# DA14586 register map
Vendor: Dialog; Series: DA1458x; File version: 1.2
CPU: CM0 r1p0, little endian, MPU, FPU, 3 interrupt priority bits
Registers are 16-bit, read-write, reset 0x0 unless marked. A register's access mark holds for its fields unless they carry their own. Offsets are from the block's base; [hi:lo] are bit positions; {n}, {i} and the like mark numbered series.

## ble580_gr01 — ble580_gr01 registers
Base 0x40000000
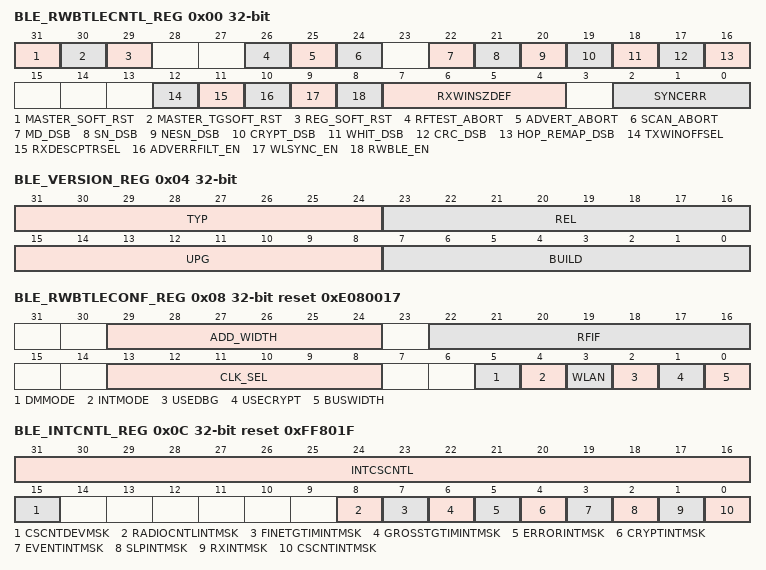
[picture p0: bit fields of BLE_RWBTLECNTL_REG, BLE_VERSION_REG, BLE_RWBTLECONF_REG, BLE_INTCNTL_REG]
0x00 BLE_RWBTLECNTL_REG 32-bit (reset mask 0x7FFFFFFF) — BLE Control register
  [31] MASTER_SOFT_RST — Reset the complete system except registers and timing generator, when written with a 1. Resets at 0 when action is performed. No action happens if it is written with 0.
  [30] MASTER_TGSOFT_RST — Reset the timing generator, when written with a 1. Resets at 0 when action is performed. No action happens if it is written with 0.
  [29] REG_SOFT_RST — Reset the complete register block, when written with a 1. Resets at 0 when action is performed. No action happens if it is written with 0.
  [26] RFTEST_ABORT — Abort the current RF Testing defined as per CS-FORMAT when written with a 1. Resets at 0 when action is performed. No action happens if it is written with 0. Note that when RFTEST_ABORT is requested. 1) In case of infinite Tx, the Packet Controller FSM stops at the end of the current byte in process, and processes accordingly the packet CRC. 2) In case of Infinite Rx, the Packet Controller FSM either stops as the end of the current Packet reception (if Access address has been detected), or simply stop the processing switching off the RF.
  [25] ADVERT_ABORT — Abort the current Advertising event when written with a 1. Resets at 0 when action is performed. No action happens if it is written with 0.
  [24] SCAN_ABORT — Abort the current scan window when written with a 1. Resets at 0 when action is performed. No action happens if it is written with 0.
  [22] MD_DSB — 0: Normal operation of MD bits management 1: Allow a single Tx/Rx exchange whatever the MD bits are
  [21] SN_DSB — 0: Normal operation of Sequence number 1: Sequence Number Management disabled: value forced by SW from Tx Descriptor value ignored in Rx, meaning that no SN error reported.
  [20] NESN_DSB — 0: Normal operation of Sequence number 1: Sequence Number Management disabled: value forced by SW from Tx Descriptor value ignored in Rx, meaning that no SN error reported.
  [19] CRYPT_DSB — 0: Normal operation. Encryption / Decryption enabled. 1: Encryption / Decryption disabled. Note that if CS-CRYPT_EN is set, then MIC is generated, and only data encryption is disabled, meaning data sent are plain data.
  [18] WHIT_DSB — 0: Normal operation. Whitening enabled. 1: Whitening disabled.
  [17] CRC_DSB — 0: Normal operation. CRC removed from data stream. 1: CRC stripping disabled on Rx packets, CRC replaced by 0x000 in Tx
  [16] HOP_REMAP_DSB — 0: Normal operation. Frequency Hopping Remapping algorithm enabled. 1: Frequency Hopping Remapping algorithm disabled
  [12] TXWINOFFSEL — Applicable only if device is in Initiator mode 0: Window Offset field in CONNECT_REQ comes from Tx Data Buffer 1: Window Offset field in CONNECT_REQ comes from Event Controller processing and is replaced in real time by Packet Controller
  [11] RXDESCPTRSEL — 0: Selects Rx Descriptor Pointer value from Control Structure 1: Selects Rx Descriptor Pointer value from CURRENTRXDESCPTR register
  [10] ADVERRFILT_EN — Advertising Channels Error Filtering Enable control 0: BLE Core reports all errors to BLE Software 1: BLE Core reports only correctly received packet, without error to BLE Software
  [9] WLSYNC_EN — 0: WLAN synchronization pulse generation disabled 1: WLAN synchronization pulse generation enabled
  [8] RWBLE_EN — 0: Disable BLE Core Exchange Table pre-fetch mechanism. 1: Enable BLE Core Exchange table pre-fetch mechanism.
  [7:4] RXWINSZDEF — Default Rx Window size in us. Used when device a) is master connected b) performs its second receipt. 0 is not a valid value. Recommended value is 10.
  [2:0] SYNCERR — Indicates the maximum number of errors allowed to recognize the synchronization word.
0x04 BLE_VERSION_REG 32-bit (reset mask 0x7FFFFFFF) — Version register
  [31:24] TYP ro — BLE Core Type - 0x6 means BT4.0 (i.e correspond LL version assigned number)
  [23:16] REL ro — BLE Core version - Major release number.(Correspond to FS v1.11)
  [15:8] UPG ro — BLE Core upgrade - Upgrade number. (Correspond to FS v1.11)
  [7:0] BUILD ro — BLE Core Build - Build number
0x08 BLE_RWBTLECONF_REG 32-bit reset 0xE080017 — Configuration register
  [29:24] ADD_WIDTH ro — Value of the BLE_ADDRESS_WIDTH parameter converted into binary.
  [22:16] RFIF ro — Supported radio interfaces. 0001000: on-chip radio others: reserved
  [13:8] CLK_SEL ro — Operating Frequency (in MHz). This field is a copy of the BLE_CNTL2_REG[BLE_CLK_SEL] value.
  [5] DMMODE ro — 0: BLE Core is used as a standalone BLE device 1: BLE Core is used in a Dual Mode device
  [4] INTMODE ro — 0: Interrupts are edge level generated, i.e pulse. 1: Interrupts are trigger level generated, i.e stays active at 1 till acknowledgement
  [3] WLAN ro — 0: WLAN Coexistence mechanism not present 1: WLAN Coexistence mechanism present
  [2] USEDBG ro — 0: Diagnostic port not instantiated 1: Diagnostic port instantiated
  [1] USECRYPT ro — 0: Encryption block not present 1: Encryption block present
  [0] BUSWIDTH ro — Processor bus width: 0: 16 bits 1: 32 bits
0x0C BLE_INTCNTL_REG 32-bit reset 0xFF801F (reset mask 0x7FFFFFFF) — Interrupt controller register
  [31:16] INTCSCNTL — Selection of the CS counter that generates an interrupt. For example, if INTCNTL[3] is set, an interrupt is sent each time CS counter equals 3.
  [15] CSCNTDEVMSK — CSCNT interrupt mask during event. This bit allows to enable CSCNT interrupt generation during events (i.e advertising, scanning, initiating, and connection) 0: CSCNT Interrupt not generated during events. 1: CSCNT Interrupt generated during events.
  [8] RADIOCNTLINTMSK — Radio Controller interrupt mask 0: Interrupt not generated 1: Interrupt generated
  [7] FINETGTIMINTMSK — Fine Target Timer Mask 0: Interrupt not generated 1: Interrupt generated
  [6] GROSSTGTIMINTMSK — Gross Target Timer Mask 0: Interrupt not generated 1: Interrupt generated
  [5] ERRORINTMSK — Error Interrupt Mask 0: Interrupt not generated 1: Interrupt generated
  [4] CRYPTINTMSK — Encryption / Decryption Interrupt Mask 0: Interrupt not generated 1: Interrupt generated
  [3] EVENTINTMSK — End of event Interrupt Mask 0: Interrupt not generated 1: Interrupt generated
  [2] SLPINTMSK — Sleep Mode Interrupt Mask 0: Interrupt not generated 1: Interrupt generated
  [1] RXINTMSK — Rx Interrupt Mask 0: Interrupt not generated 1: Interrupt generated
  [0] CSCNTINTMSK — 625usec Base Time Interrupt Mask. 0: Interrupt not generated. 1: Interrupt generated
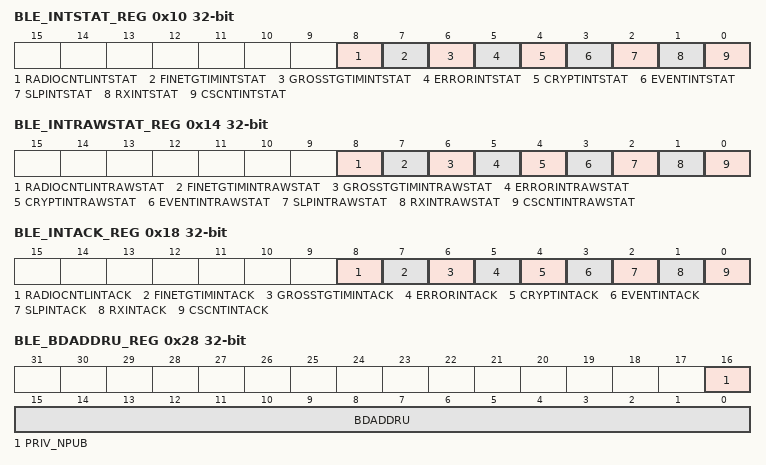
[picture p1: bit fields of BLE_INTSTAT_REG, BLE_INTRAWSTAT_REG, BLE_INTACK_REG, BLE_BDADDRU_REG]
0x10 BLE_INTSTAT_REG 32-bit — Interrupt status register
  [8] RADIOCNTLINTSTAT ro — Radio Controller interrupt status 0: No Gross Target Timer interrupt. 1: A Gross Target Timer interrupt is pending.
  [7] FINETGTIMINTSTAT ro — Masked Fine Target Timer Error interrupt status 0: No Fine Target Timer interrupt. 1: A Fine Target Timer interrupt is pending.
  [6] GROSSTGTIMINTSTAT ro — Masked Gross Target Timer interrupt status 0: No Gross Target Timer interrupt. 1: A Gross Target Timer interrupt is pending.
  [5] ERRORINTSTAT ro — Masked Error interrupt status 0: No Error interrupt. 1: An Error interrupt is pending.
  [4] CRYPTINTSTAT ro — Masked Encryption/Decryption interrupt status 0: No Encryption / Decryption interrupt. 1: An Encryption / Decryption interrupt is pending.
  [3] EVENTINTSTAT ro — Masked End of Event interrupt status 0: No End of Advertising / Scanning / Connection interrupt. 1: An End of Advertising / Scanning / Connection interrupt is pending.
  [2] SLPINTSTAT ro — Masked Sleep interrupt status 0: No End of Sleep Mode interrupt. 1: An End of Sleep Mode interrupt is pending.
  [1] RXINTSTAT ro — Masked Packet Reception interrupt status 0: No Rx interrupt. 1: An Rx interrupt is pending.
  [0] CSCNTINTSTAT ro — Masked 625us base time reference interrupt status 0: No 625us Base Time interrupt. 1: A 625us Base Time interrupt is pending.
0x14 BLE_INTRAWSTAT_REG 32-bit — Interrupt raw status register
  [8] RADIOCNTLINTRAWSTAT ro — Radio Controller interrupt raw status 0: No Gross Target Timer interrupt. 1: A Gross Target Timer interrupt is pending.
  [7] FINETGTIMINTRAWSTAT ro — Fine Target Timer Error interrupt raw status 0: No Fine Target Timer interrupt. 1: A Fine Target Timer interrupt is pending.
  [6] GROSSTGTIMINTRAWSTAT ro — Gross Target Timer interrupt raw status 0: No Gross Target Timer interrupt. 1: A Gross Target Timer interrupt is pending.
  [5] ERRORINTRAWSTAT ro — Error interrupt raw status 0: No Error interrupt. 1: An Error interrupt is pending.
  [4] CRYPTINTRAWSTAT ro — Encryption/Decryption interrupt raw status 0: No Encryption / Decryption interrupt. 1: An Encryption / Decryption interrupt is pending.
  [3] EVENTINTRAWSTAT ro — End of Event interrupt raw status 0: No End of Advertising / Scanning / Connection interrupt. 1: An End of Advertising / Scanning / Connection interrupt is pending.
  [2] SLPINTRAWSTAT ro — Sleep interrupt raw status 0: No End of Sleep Mode interrupt. 1: An End of Sleep Mode interrupt is pending.
  [1] RXINTRAWSTAT ro — Packet Reception interrupt raw status 0: No Rx interrupt. 1: An Rx interrupt is pending.
  [0] CSCNTINTRAWSTAT ro — 625us base time reference interrupt raw status 0: No 625us Base Time interrupt. 1: A 625us Base Time interrupt is pending.
0x18 BLE_INTACK_REG 32-bit — Interrupt acknowledge register
  [8] RADIOCNTLINTACK wo — Radio Controller interrupt acknowledgement bit Software writing 1 acknowledges the Error interrupt. This bit resets RADIOCNTLINTSTAT and RADIOCNTLINTRAWSTAT flags.
  [7] FINETGTIMINTACK wo — Fine Target Timer interrupt acknowledgement bit Software writing 1 acknowledges the Error interrupt. This bit resets FINETGTIMINTSTAT and FINETGTIMINTRAWSTAT flags.
  [6] GROSSTGTIMINTACK wo — Gross Target Timer interrupt acknowledgement bit Software writing 1 acknowledges the Error interrupt. This bit resets GROSSTGTIMINTSTAT and GROSSTGTIMINTRAWSTAT flags.
  [5] ERRORINTACK wo — Error interrupt acknowledgement bit Software writing 1 acknowledges the Error interrupt. This bit resets ERRORINTSTAT and ERRORINTRAWSTAT flags.
  [4] CRYPTINTACK wo — Encryption/Decryption interrupt acknowledgement bit Software writing 1 acknowledges the Encryption / Decryption interrupt. This bit resets CRYPTINTSTAT and CRYPTINTRAWSTAT flags.
  [3] EVENTINTACK wo — End of Event interrupt acknowledgment bit Software writing 1 acknowledges the End of Advertising / Scanning / Connection interrupt. This bit resets SLPINTSTAT and SLPINTRAWSTAT flags.
  [2] SLPINTACK wo — End of Deep Sleep interrupt acknowledgment bit Software writing 1 acknowledges the End of Sleep Mode interrupt. This bit resets SLPINTSTAT and SLPINTRAWSTAT flags.
  [1] RXINTACK wo — Packet Reception interrupt acknowledgment bit Software writing 1 acknowledges the Rx interrupt. This bit resets RXINTSTAT and RXINTRAWSTAT flags.
  [0] CSCNTINTACK wo — 625us base time reference interrupt acknowledgment bit Software writing 1 acknowledges the CLKN interrupt. This bit resets CLKINTSTAT and CLKINTRAWSTAT flags.
0x1C BLE_BASETIMECNT_REG 32-bit — Base time reference counter
  [26:0] BASETIMECNT ro — Value of the 625us base time reference counter. Updated each time BLE_SAMPLECLK_REG[SAMP] is written. Used by the SW in order to synchronize with the HW.
0x20 BLE_FINETIMECNT_REG 32-bit — Fine time reference counter
  [9:0] FINECNT ro — Value of the current usec fine time reference counter. Updated each usec. Used by the SW in order to synchronize with the HW, and obtain a more precise sleep duration
0x24 BLE_BDADDRL_REG 32-bit (reset mask 0x7FFFFFFF) — BLE device address LSB register
  [31:0] BDADDRL — Bluetooth Low Energy Device Address. LSB part.
0x28 BLE_BDADDRU_REG 32-bit — BLE device address MSB register
  [16] PRIV_NPUB — Bluetooth Low Energy Device Address privacy indicator 0: Public Bluetooth Device Address 1: Private Bluetooth Device Address
  [15:0] BDADDRU — Bluetooth Low Energy Device Address. MSB part.
0x2C BLE_CURRENTRXDESCPTR_REG 32-bit — Rx Descriptor Pointer for the Receive Buffer Chained List
  [13:0] CURRENTRXDESCPTR — Rx Descriptor Pointer that determines the starting point of the Receive Buffer Chained List.
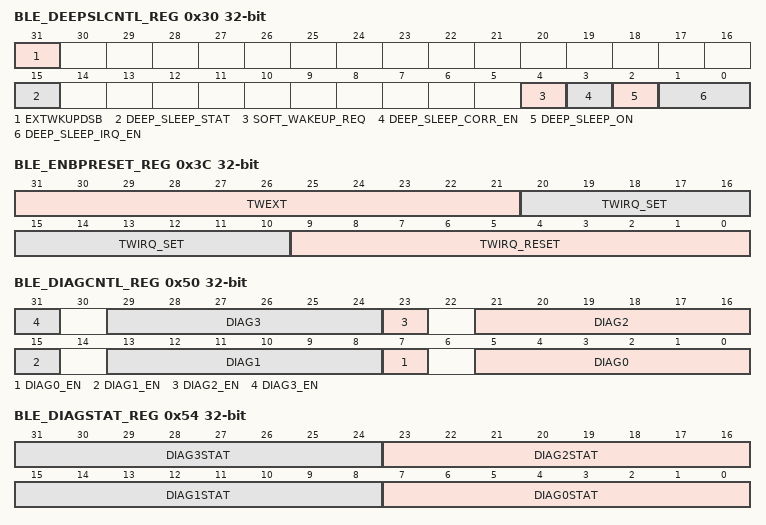
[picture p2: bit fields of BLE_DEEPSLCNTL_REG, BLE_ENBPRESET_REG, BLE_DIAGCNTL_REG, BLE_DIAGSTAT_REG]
0x30 BLE_DEEPSLCNTL_REG 32-bit (reset mask 0x7FFFFFFF) — Deep-Sleep control register
  [31] EXTWKUPDSB — External Wake-Up disable 0: BLE Core can be woken by external wake-up 1: BLE Core cannot be woken up by external wake-up
  [15] DEEP_SLEEP_STAT ro — Indicator of current Deep Sleep clock mux status: 0: BLE Core is not yet in Deep Sleep Mode 1: BLE Core is in Deep Sleep Mode (only Low Power Clock is running)
  [4] SOFT_WAKEUP_REQ — Wake Up Request from BLE Software. Applies when system is in Deep Sleep Mode. It wakes up the BLE Core when written with a 1. Always read as 0. No action happens if it is written with 0.
  [3] DEEP_SLEEP_CORR_EN — 625us base time reference integer and fractional part correction. Applies when system has been woken-up from Deep Sleep Mode. It enables Fine Counter and Base Time counter when written with a 1. Always read as 0. No action happens if it is written with 0.
  [2] DEEP_SLEEP_ON — 0: BLE Core in normal active mode 1: Request BLE Core to switch in deep sleep mode. This bit is reset on DEEP_SLEEP_STAT falling edge.
  [1:0] DEEP_SLEEP_IRQ_EN — Always set to '3' when DEEP_SLEEP_ON is set to '1'. It controls the generation of BLE_WAKEUP_LP_IRQ.
0x34 BLE_DEEPSLWKUP_REG 32-bit (reset mask 0x7FFFFFFF) — Time (measured in Low Power clock cycles) in Deep Sleep Mode before waking-up the device
  [31:0] DEEPSLTIME — Determines the time in Low Power Clock cycles to spend in Deep Sleep Mode before waking-up the device. This ensures a maximum of 37 hours and 16mn sleep mode capabilities at 32kHz. This ensures a maximum of 36 hours and 16mn sleep mode capabilities at 32.768kHz. If DEEPSLTIME is set to zero, the Deep Sleep Time duration is considered as infinite, and only wake up requests can restore active behaviour BLE Software must ensure DEEPSLTIME value to be greater than 2 in order to cope with control resynchronization requirements
0x38 BLE_DEEPSLSTAT_REG 32-bit (reset mask 0x7FFFFFFF) — Duration of the last deep sleep phase register
  [31:0] DEEPSLDUR ro — Actual duration of the last deep sleep phase measured in Low Power Clock cycles. DEEPSLDUR is set to zero at the beginning of the deep sleep phase, and is incremented at each Low Power Clock cycle until the end of the deep sleep phase.
0x3C BLE_ENBPRESET_REG 32-bit (reset mask 0x7FFFFFFF) — Time in low power oscillator cycles register
  [31:21] TWEXT — Minimum and recommended value is 'TWIRQ_RESET + 1'. In the case of wake-up due to an external wake-up request, TWEXT specifies the time delay in low power oscillator cycles to deassert BLE_WAKEUP_LP_IRQ. Refer also to GP_CONTROL_REG[BLE_WAKEUP_REQ]. Range is [0...64 ms] for 32kHz; [0...62.5 ms] for 32.768kHz
  [20:10] TWIRQ_SET — Minimum value is 'TWIRQ_RESET + 1'. Time in low power oscillator cycles to set BLE_WAKEUP_LP_IRQ before the BLE sleep timer expiration. Refer also to BLE_DEEPSLWKUP_REG[DEEPSLTIME]. Range is [0...64 ms] for 32kHz; [0...62.5 ms] for 32.768kHz
  [9:0] TWIRQ_RESET — Recommended value is 1. Time in low power oscillator cycles to reset BLE_WAKEUP_LP_IRQ before the BLE sleep timer expiration. Refer also to BLE_DEEPSLWKUP_REG[DEEPSLTIME]. Range is [0...32 ms] for 32kHz; [0...31.25 ms] for 32.768kHz.
0x40 BLE_FINECNTCORR_REG 32-bit — Phase correction value register
  [9:0] FINECNTCORR — Phase correction value for the 625usec reference counter (i.e Fine Counter) in us.
0x44 BLE_BASETIMECNTCORR_REG 32-bit — Base Time Counter
  [26:0] BASETIMECNTCORR — Base Time Counter correction value.
0x50 BLE_DIAGCNTL_REG 32-bit (reset mask 0x7FFFFFFF) — Diagnostics Register
  [8n+7] DIAG{n}_EN (n=0..3) — 0: Disable diagnostic port {n} output. All outputs are set to 0. 1: Enable diagnostic port {n} output.
  [8n+5:8n] DIAG{n} (n=0..3) — Only relevant when DIAG{n}_EN = 1. Selection of the outputs that must be driven to the diagnostic port {n}.
0x54 BLE_DIAGSTAT_REG 32-bit (reset mask 0x7FFFFFFF) — Debug use only
  [8n+7:8n] DIAG{n}STAT ro (n=0..3) — Directly connected to ble_dbg{n}[7:0] output. Debug use only.
0x58 BLE_DEBUGADDMAX_REG 32-bit — Upper limit for the memory zone
  [15:0] ADDMAX — Upper limit for the memory zone.
0x5C BLE_DEBUGADDMIN_REG 32-bit — Lower limit for the memory zone
  [15:0] ADDMIN — Lower limit for the memory zone.
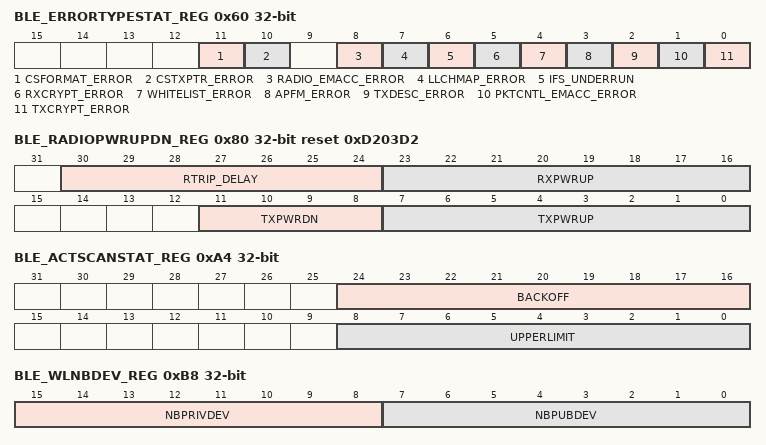
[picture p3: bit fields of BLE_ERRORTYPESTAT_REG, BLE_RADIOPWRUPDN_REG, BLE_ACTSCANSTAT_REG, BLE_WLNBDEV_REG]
0x60 BLE_ERRORTYPESTAT_REG 32-bit — Error Type Status registers
  [11] CSFORMAT_ERROR ro — Indicates whether CS-FORMAT has been programmed with an invalid value: this is a major software programming failure. 0: No error 1: Error occurred
  [10] CSTXPTR_ERROR ro — Indicates whether CS-TXPTR is null, this is a major software programming failure. 0: No error 1: Error occurred
  [8] RADIO_EMACC_ERROR ro — Radio Controller Exchange Memory access error, happens when Exchange Memory access are not served in time and data are corrupted. 0: No error 1: Error occurred
  [7] LLCHMAP_ERROR ro — Link Layer Channel Map error, happens when actual number of CS-LLCHMAP bit set to one is different from CS-NBCHGOOD at the beginning of Frequency Hopping process 0: No error 1: Error occurred
  [6] IFS_UNDERRUN ro — Inter Frame Space Under run, occurs if IFS time is not enough to update and read Control Structure/Descriptors, and/or White List parsing is not finished and/or Decryption time is too long to be finished on time 0: No error 1: Error occurred
  [5] RXCRYPT_ERROR ro — Real Time Decryption Error, happens when decryption is not finished before IFS time 0: No error 1: Error occurred
  [4] WHITELIST_ERROR ro — White List Timeout Error, occurs if White List parsing is not finished on time 0: No error 1: Error occurred
  [3] APFM_ERROR ro — Anticipated Pre-Fetch Mechanism error, happens when 3 consecutive Exchange Table entry have been programmed, 0: no error 1: Error occured
  [2] TXDESC_ERROR ro — Tx Descriptor Error, happens when fetched Tx Descriptor has TXDONE bit not set 0: No error 1: Error occurred
  [1] PKTCNTL_EMACC_ERROR ro — Packet Controller Exchange Memory access error, happens when Exchange Memory access are not served in time and Tx/Rx data are corrupted 0: No error 1: Error occurred
  [0] TXCRYPT_ERROR ro — Real Time Encryption Error, happens when encryption is not finished before Tx Payload has to be sent 0: No error 1: Error occurred
0x64 BLE_SWPROFILING_REG 32-bit (reset mask 0x7FFFFFFF) — Software Profiling register
  [31:0] SWPROFVAL — Software Profiling register: used by BLE Software for profiling purpose: this value is copied on Diagnostic port
0x70 BLE_RADIOCNTL0_REG 32-bit reset 0x2102 — Radio interface control register
  [22] DPCORR_EN — Enable the use of delayed DC compensated data path in Radio Correlator block 1: Enable 0: Disable Must be set to '0'.
0x74 BLE_RADIOCNTL1_REG 32-bit — Radio interface control register
  [20:16] XRFSEL — Extended radio selection field, Must be set to '00011'.
0x80 BLE_RADIOPWRUPDN_REG 32-bit reset 0xD203D2 — RX/TX power up/down phase register
  [30:24] RTRIP_DELAY — Defines round trip delay value. This value correspond to the addition of data latency in Tx and data latency in Rx. Value is in us.
  [23:16] RXPWRUP — This register holds the length in us of the Rx power up phase for the current radio device. Default value is 210 us (reset value). Operating range depends of the selected radio.
  [11:8] TXPWRDN — This register extends the length in us of the Tx power down phase for the current radio device. Default value is 3us (reset value). Operating range depends of the selected radio.
  [7:0] TXPWRUP — This register holds the length in us of the Tx power up phase for the current radio device. Default value is 210 us (reset value). Operating range depends of the selected radio.
0x90 BLE_ADVCHMAP_REG 32-bit reset 0x7 — Advertising Channel Map
  [2:0] ADVCHMAP — Advertising Channel Map, defined as per the advertising connection settings. Contains advertising channels index 37 to 39. If ADVCHMAP[i] equals: 0: Do not use data channel i+37. 1: Use data channel i+37.
0xA0 BLE_ADVTIM_REG 32-bit — Advertising Packet Interval
  [13:0] ADVINT — Advertising Packet Interval defines the time interval in between two ADV_xxx packet sent. Value is in usec. Value to program depends of the used Advertising Packet type and the device filtering policy. Please refer to Table 3-10 for details about ADVINT programming range.
0xA4 BLE_ACTSCANSTAT_REG 32-bit — Active scan register
  [24:16] BACKOFF — Active scan mode back-off counter initialization value.
  [8:0] UPPERLIMIT — Active scan mode upper limit counter value.
0xB0 BLE_WLPUBADDPTR_REG 32-bit — Start address of public devices list
  [15:0] WLPUBADDPTR — Start address pointer of the public devices white list.
0xB4 BLE_WLPRIVADDPTR_REG 32-bit — Start address of private devices list
  [15:0] WLPRIVADDPTR — Start address pointer of the private devices white list.
0xB8 BLE_WLNBDEV_REG 32-bit — Devices in white list
  [15:8] NBPRIVDEV — Number of private devices in the white list.
  [7:0] NBPUBDEV — Number of public devices in the white list.
0xC0 BLE_AESCNTL_REG 32-bit — Start AES register
  [0] AES_START — Writing a 1 starts AES-128 ciphering process. This bit is reset once the process is finished (i.e BLE_CRYPT_IRQ interrupt occurs, even masked)
0xC4 BLE_AESKEY31_0_REG 32-bit (reset mask 0x7FFFFFFF) — AES encryption key
  [31:0] AESKEY31_0 — AES encryption 128-bit key. Bit 31 down to 0
0xC8 BLE_AESKEY63_32_REG 32-bit (reset mask 0x7FFFFFFF) — AES encryption key
  [31:0] AESKEY63_32 — AES encryption 128-bit key. Bit 63 down to 32
0xCC BLE_AESKEY95_64_REG 32-bit (reset mask 0x7FFFFFFF) — AES encryption key
  [31:0] AESKEY95_64 — AES encryption 128-bit key. Bit 95 down to 64
0xD0 BLE_AESKEY127_96_REG 32-bit (reset mask 0x7FFFFFFF) — AES encryption key
  [31:0] AESKEY127_96 — AES encryption 128-bit key. Bit 127 down to 96
0xD4 BLE_AESPTR_REG 32-bit — Pointer to the block to encrypt/decrypt
  [15:0] AESPTR — Pointer to the memory zone where the block to encrypt/decrypt is stored.
0xD8 BLE_TXMICVAL_REG 32-bit (reset mask 0x7FFFFFFF) — AES / CCM plain MIC value
  [31:0] TXMICVAL ro — AES / CCM plain MIC value. Valid on BLE_CRYPT_IRQ interrupt (even masked)
0xDC BLE_RXMICVAL_REG 32-bit (reset mask 0x7FFFFFFF) — AES / CCM plain MIC value
  [31:0] RXMICVAL ro — AES / CCM plain MIC value. Valid on BLE_CRYPT_IRQ interrupt (even masked)
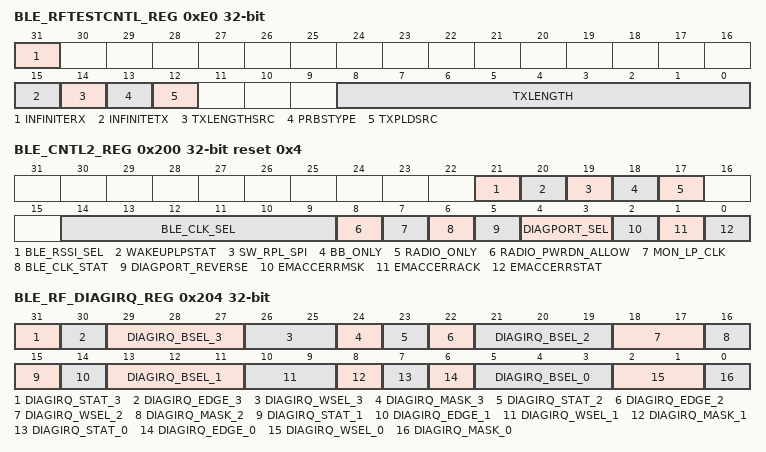
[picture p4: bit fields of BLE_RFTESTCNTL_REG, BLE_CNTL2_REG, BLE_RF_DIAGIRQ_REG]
0xE0 BLE_RFTESTCNTL_REG 32-bit (reset mask 0x7FFFFFFF) — RF Testing Register
  [31] INFINITERX — Applicable for all frame format 0: Normal mode of operation 1: Infinite Rx window
  [15] INFINITETX — Applicable for all frame format 0: Normal mode of operation. 1: Infinite Tx packet / Normal start of a packet but endless payload In case of infinite Tx payload, and when PRBS source is not selected, then RFTESTCNTL-TXLENGTH field provides the length of the pattern to repeat in the payload.
  [14] TXLENGTHSRC — Applicable only in Tx/Rx RF Test mode 0: Normal mode of operation: TXDESC-TXADVLEN controls the Tx packet payload size 1: Uses RFTESTCNTL-TXLENGTH packet length (can support up to 512 bytes transmit)
  [13] PRBSTYPE — Applicable only in Tx/Rx RF Test mode 0: Tx Packet Payload are PRBS9 type 1: Tx Packet Payload are PRBS15 type PRBS9 is defined as p(x)=1+x5+x9. The LFSR used for the PRBS9 generator must be initialized with 0x1FF value. PRBS15 is defined as p(x)=1+x+x2+x12+x13+x14. The LFSR used for the PRBS15 generator must be initialized with 0x7FFF value.
  [12] TXPLDSRC — Applicable only in Tx/Rx RF Test mode 0: Tx Packet Payload source is the Control Structure 1: Tx Packet Payload are PRBS generator
  [8:0] TXLENGTH — Applicable only in Tx/Rx RF Test mode Tx packet length in number of byte
0xF0 BLE_TIMGENCNTL_REG 32-bit — Timing Generator Register
  [7:0] PREFTECH_TIME — Defines Exchange Table pre-fetch instant in us
0xF4 BLE_GROSSTIMTGT_REG 32-bit — Gross Timer Target value
  [15:0] GROSSTARGET — Gross Timer Target value on which a BLE_GROSSTGTIM_IRQ must be generated. This timer has a precision of 10ms: interrupt is generated only when GROSSTARGET[15:0] = BASETIMECNT[19:4] and BASETIMECNT[3:0] = 0.
0xF8 BLE_FINETIMTGT_REG 32-bit — Fine Timer Target value
  [26:0] FINETARGET — Fine Timer Target value on which a BLE_FINETGTIM_IRQ must be generated. This timer has a precision of 625us: interrupt is generated only when FINETARGET = BASETIMECNT
0xFC BLE_SAMPLECLK_REG 32-bit — Samples the Base Time Counter
  [0] SAMP — Writing a 1 samples the Base Time Counter value in BASETIMECNT register. Resets at 0 when action is performed.
0x200 BLE_CNTL2_REG 32-bit reset 0x4 — BLE Control Register 2
  [21] BLE_RSSI_SEL — 0: Select Peak-hold RSSI value (default). 1: Select current Average RSSI value.
  [20] WAKEUPLPSTAT ro — The status of the BLE_WAKEUP_LP_IRQ. The Interrupt Service Routine of BLE_WAKEUP_LP_IRQ should return only when the WAKEUPLPSTAT is cleared. Note that BLE_WAKEUP_LP_IRQ is automatically acknowledged after the power up of the Radio Subsystem, plus one Low Power Clock period.
  [19] SW_RPL_SPI — Keep to 0.
  [18] BB_ONLY — Keep to 0.
  [17] RADIO_ONLY — Keep to 0.
  [14:9] BLE_CLK_SEL — BLE Clock Select. Specifies the BLE master clock absolute frequency in MHz. Typical values are 16 and 8. Value depends on the selected XTAL frequency and the value of CLK_RADIO_REG[BLE_DIV] bitfield. For example, if XTAL oscillates at 16MHz and CLK_RADIO_REG[BLE_DIV] = 1 (divide by 2), then BLE master clock frequency is 8MHz and BLE_CLK_SEL should be set to value 8. The selected BLE master clock frequency (affected by BLE_DIV and BLE_CLK_SEL) must be modified and set only during the initialization time, i.e. before setting BLE_RWBTLECNTL_REG[RWBLE_EN] to 1. Refer also to BLE_RWBTLECONF_REG[CLK_SEL].
  [8] RADIO_PWRDN_ALLOW ro — This active high signal indicates when it is allowed for the BLE core (embedded in the Radio sub-System power domain) to be powered down. After the assertion of the BLE_DEEPSLCNTL_REG[DEEP_SLEEP_ON] a hardware sequence based on the Low Power clock will cause the assertion of RADIO_PWRDN_ALLOW. The RADIO_PWRDN_ALLOW will be cleared to '0' when the BLE core exits from the sleep state, i.e. when the BLE_SLP_IRQ will be asserted.
  [7] MON_LP_CLK — The SW can only write a '0' to this bit. Whenever a positive edge of the low power clock used by the BLE Timers is detected, then the HW will automatically set this bit to '1'. This functionality will not work if BLE Timer is in reset state (refer to CLK_RADIO_REG[BLE_LP_RESET]). This bit can be used for SW synchronization, to debug the low power clock, etc.
  [6] BLE_CLK_STAT ro — 0: BLE uses low power clock 1: BLE uses master clock
  [5] DIAGPORT_REVERSE — BLE/RADIO Diagnostic Port Reverse order. When this bit is '1', the mapping of the diagnostic bus DIAGPORT[7:0] (controlled by DIAGPORT_SEL) to GPIOs (controlled by Pxy_MODE_REG[PID]) is reversed. The mapping is: If '0' then DIAGPORT[7] is mapped to P0[7], etc. DIAGPORT[4] is mapped to P0[4], DIAGPORT[3] is mapped to P0[3] and P1[3], etc. and DIAGPORT[0] is mapped to P0[0] and P1[0]. If '1' then DIAGPORT[7] is mapped to P0[0] and P1[0], etc. DIAGPORT[4] is mapped to P0[3] and P1[3], DIAGPORT[3] is mapped to P0[4], etc. and DIAGPORT[0] is mapped to P0[7].
  [4:3] DIAGPORT_SEL — BLE/RADIO Diagnostic Port Selection. Controls the multiplexing of the internal diagnostic signals towards the 8-bit diagnostic bus DIAGPORT[7:0]. The DIAGPORT[7:0] bit order may or may not be reversed by using the DIAGPORT_REVERSE bitfield and then it will be directed to the GPIOs P0[7:0] and P1[3:0]. (Note that the P1[3:0] diagnostic signals are the same with P0[3:0] signals.) The DIAGPORT[7:0] value, depending on the DIAGPORT_SEL value, is: 00: {BLE_DIAG2[7:5], BLE_DIAG1[4:3], BLE_DIAG0[2:0]} 01: {BLE_DIAG2[7:5], BLE_DIAG1[4:3], BLE_DIAG0[2] , wakeup_lp_irq, deep_sleep_stat_32k} 10: RADIO_DIAG0[7:0] 11: RADIO_DIAG1[7:0]
  [2] EMACCERRMSK — Exchange Memory Access Error Mask: When cleared to '0' the EM_ACC_ERR will not cause an BLE_ERROR_IRQ interrupt. When set to '1' an BLE_ERROR_IRQ will be generated as long as EM_ACC_ERR is '1'.
  [1] EMACCERRACK wo — Exchange Memory Access Error Acknowledge. When the SW writes a '1' to this bit then the EMACCERRSTAT bit will be cleared. When the SW writes '0' it will have no affect. The read value is always '0'.
  [0] EMACCERRSTAT ro — Exchange Memory Access Error Status: The bit is read-only and can be cleared only by writing a '1' at EMACCERRACK bitfield. This bit will be set to '1' by the hardware when the controller will access an EM page that is not mapped according to the EM_MAPPING value. When this bit is '1' then the BLE_ERROR_IRQ will be asserted as long as EMACCERRMSK is '1'.
0x204 BLE_RF_DIAGIRQ_REG 32-bit (reset mask 0x7FFFFFFF) — BLE/RF Diagnostic IRQ Control Register
  [31] DIAGIRQ_STAT_3 ro — Same as DIAGIRQ_STAT_0.
  [30] DIAGIRQ_EDGE_3 — Same as DIAGIRQ_EDGE_0.
  [29:27] DIAGIRQ_BSEL_3 — Same as DIAGIRQ_BSEL_0.
  [26:25] DIAGIRQ_WSEL_3 — Same as DIAGIRQ_WSEL_0.
  [24] DIAGIRQ_MASK_3 — Same as DIAGIRQ_MASK_0.
  [23] DIAGIRQ_STAT_2 ro — Same as DIAGIRQ_STAT_0.
  [22] DIAGIRQ_EDGE_2 — Same as DIAGIRQ_EDGE_0.
  [21:19] DIAGIRQ_BSEL_2 — Same as DIAGIRQ_BSEL_0.
  [18:17] DIAGIRQ_WSEL_2 — Same as DIAGIRQ_WSEL_0.
  [16] DIAGIRQ_MASK_2 — Same as DIAGIRQ_MASK_0.
  [15] DIAGIRQ_STAT_1 ro — Same as DIAGIRQ_STAT_0.
  [14] DIAGIRQ_EDGE_1 — Same as DIAGIRQ_EDGE_0.
  [13:11] DIAGIRQ_BSEL_1 — Same as DIAGIRQ_BSEL_0.
  [10:9] DIAGIRQ_WSEL_1 — Same as DIAGIRQ_WSEL_0.
  [8] DIAGIRQ_MASK_1 — Same as DIAGIRQ_MASK_0.
  [7] DIAGIRQ_STAT_0 ro — Diagnostic IRQ Status 0 This bit is read only. It is automatically cleared to '0' on each read of the BLE_RF_DIAGIRQ_REG register. It is automatically asserted to '1' on each detection of the selected edge, of the selected bit, of the selected word.
  [6] DIAGIRQ_EDGE_0 — Diagnostic IRQ Edge 0 Selects the edge of the selected bit (refer to DIAGIRQ_BSEL_0) that will trigger the assertion of DIAGIRQ_STAT_0. If '0' then the positive edge is selected, when '1' the negative edge is selected.
  [5:3] DIAGIRQ_BSEL_0 — Diagnostic IRQ Bit Select 0 Selects the bit of the 8-bit bus (as selected by the DIAGIRQ_WSEL_0) that will be used for the IRQ generation.
  [2:1] DIAGIRQ_WSEL_0 — Diagnostic IRQ Word Select 0 Selects the 8-bit diagnostic bus that will be used for the IRQ generation. 00: Selects the BLE_DIAG0 01: Selects the BLE_DIAG1 10: Selects the RADIO_DIAG0 11: Selects the RADIO_DIAG1
  [0] DIAGIRQ_MASK_0 — Diagnostic IRQ Mask 0 When set to '1' a BLE_RF_DIAG_IRQ will be generated on each rise of the DIAGIRQ_STAT_0 bit. When cleared to '0' no IRQ will be generated.
